# ATtiny45 register map
Vendor: Atmel; File version: 1.0
CPU: other r0p0, little endian, no MPU, no FPU, 4 interrupt priority bits
Registers are 8-bit, read-write, reset 0x0 unless marked. A register's access mark holds for its fields unless they carry their own. Offsets are from the block's base; [hi:lo] are bit positions; {n}, {i} and the like mark numbered series.

## CPU — CPU Registers
Base 0x00800031
0x00 GPIOR0 — General purpose register 0
0x01 GPIOR1 — General Purpose register 1
0x02 GPIOR2 — General Purpose IO register 2
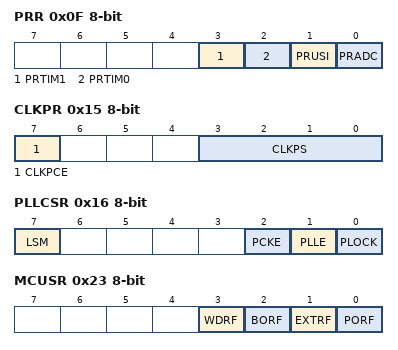
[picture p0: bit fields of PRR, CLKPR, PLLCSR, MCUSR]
0x0F PRR — Power Reduction Register
  [3] PRTIM1 — Power Reduction Timer/Counter1
  [2] PRTIM0 — Power Reduction Timer/Counter0
  [1] PRUSI — Power Reduction USI
  [0] PRADC — Power Reduction ADC
0x11 DWDR — debugWire data register (write-only for debugger)
0x15 CLKPR — Clock Prescale Register (read-only for debugger)
  [7] CLKPCE — Clock Prescaler Change Enable
  [3:0] CLKPS — Clock Prescaler Select Bits
    0=1; 1=2; 2=4; 3=8; 4=16; 5=32; 6=64; 7=128; 8=256
0x16 PLLCSR — PLL Control and status register
  [7] LSM — Low speed mode
  [2] PCKE — PCK Enable
  [1] PLLE — PLL Enable
  [0] PLOCK — PLL Lock detector
0x20 OSCCAL — Oscillator Calibration Register (read-only for debugger)
  [7:0] OSCCAL — Oscillator Calibration
0x23 MCUSR — MCU Status register (read-only for debugger)
  [3] WDRF — Watchdog Reset Flag
  [2] BORF — Brown-out Reset Flag
  [1] EXTRF — External Reset Flag
  [0] PORF — Power-On Reset Flag
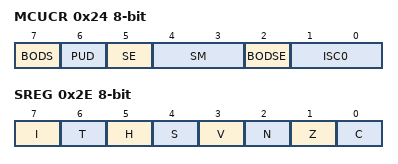
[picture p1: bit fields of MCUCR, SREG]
0x24 MCUCR — MCU Control Register
  [7] BODS — BOD Sleep
  [6] PUD — Pull-up Disable
  [5] SE — Sleep Enable
  [4:3] SM — Sleep Mode Select Bits
    0=IDLE; 1=ADC (ADC Noise Reduction (If Available)); 2=PDOWN (Power Down)
  [2] BODSE — BOD Sleep Enable
  [1:0] ISC0 — Interrupt Sense Control 0 bits
    0=LOW_LEVEL_OF_INTX; 1=ANY_LOGICAL_CHANGE_IN_INTX; 2=FALLING_EDGE_OF_INTX; 3=RISING_EDGE_OF_INTX
0x2C SP 16-bit (reset mask 0xFF) — Stack Pointer Bytes
0x2E SREG — Status Register
  [7] I — Global Interrupt Enable
  [6] T — Bit Copy Storage
  [5] H — Half Carry Flag
  [4] S — Sign Bit
  [3] V — Two's Complement Overflow Flag
  [2] N — Negative Flag
  [1] Z — Zero Flag
  [0] C — Carry Flag

## EEPROM
Base 0x0080003C
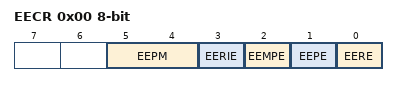
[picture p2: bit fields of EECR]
0x00 EECR — EEPROM Control Register
  [5:4] EEPM — EEPROM Programming Mode Bits
    0=ERASE_AND_WRITE_IN_ONE_OPERATION; 1=ERASE_ONLY; 2=WRITE_ONLY
  [3] EERIE — EEPROM Ready Interrupt Enable
  [2] EEMPE — EEPROM Master Write Enable
  [1] EEPE — EEPROM Write Enable
  [0] EERE — EEPROM Read Enable
0x01 EEDR — EEPROM Data Register
0x02 EEAR 16-bit (reset mask 0xFF) — EEPROM Address Register Bytes

## EXINT — External Interrupts
Base 0x00800035
0x00 PCMSK — Pin Change Enable Mask
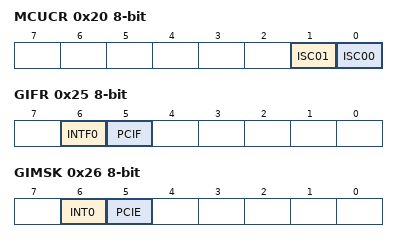
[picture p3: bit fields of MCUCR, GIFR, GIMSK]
0x20 MCUCR — MCU Control Register
  [1] ISC01 — Interrupt Sense Control 0 Bit 1
  [0] ISC00 — Interrupt Sense Control 0 Bit 0
    0=LOW_LEVEL_OF_INTX; 1=ANY_LOGICAL_CHANGE_ON_INTX
0x25 GIFR — General Interrupt Flag register (read-only for debugger)
  [6] INTF0 — External Interrupt Flag 0
  [5] PCIF — Pin Change Interrupt Flag
0x26 GIMSK — General Interrupt Mask Register
  [6] INT0 — External Interrupt Request 0 Enable
  [5] PCIE — Pin Change Interrupt Enable

## PORTB — I/O Port
Base 0x00800036
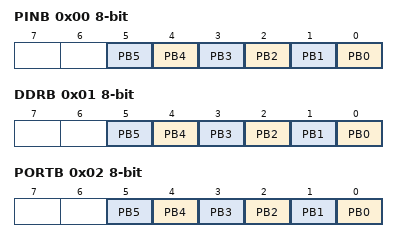
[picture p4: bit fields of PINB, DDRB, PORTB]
0x00 PINB — Input Pins, Port B (read-only for debugger)
  [n] PB{n} (n=0..5) — Pin B{n}
0x01 DDRB — Data Direction Register, Port B
  [n] PB{n} (n=0..5) — Pin B{n}
0x02 PORTB — Data Register, Port B
  [n] PB{n} (n=0..5) — Pin B{n}

## TC0 — Timer/Counter, 8-bit
Base 0x00800048
0x00 OCR0B — Timer/Counter0 Output Compare Register
0x01 OCR0A — Timer/Counter0 Output Compare Register
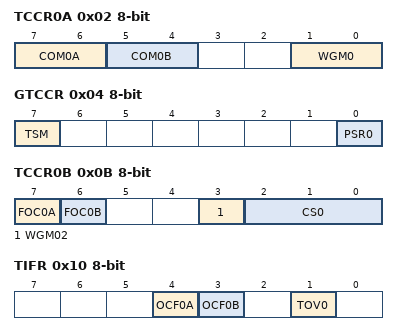
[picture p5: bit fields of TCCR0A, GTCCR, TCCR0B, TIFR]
0x02 TCCR0A — Timer/Counter Control Register A
  [7:6] COM0A — Compare Output Mode, Phase Correct PWM Mode
  [5:4] COM0B — Compare Output Mode, Fast PWm
  [1:0] WGM0 — Waveform Generation Mode
0x04 GTCCR — General Timer/Counter Control Register
  [7] TSM — Timer/Counter Synchronization Mode
  [0] PSR0 — Prescaler Reset Timer/Counter1 and Timer/Counter0
0x0A TCNT0 — Timer/Counter0
0x0B TCCR0B — Timer/Counter Control Register B
  [7] FOC0A — Force Output Compare A
  [6] FOC0B — Force Output Compare B
  [3] WGM02
  [2:0] CS0 — Clock Select
    0=NO_CLOCK_SOURCE_STOPPED; 1=RUNNING_NO_PRESCALING; 2=RUNNING_CLK_8; 3=RUNNING_CLK_64; 4=RUNNING_CLK_256; 5=RUNNING_CLK_1024; 6=RUNNING_EXTCLK_TN_FALLING_EDGE; 7=RUNNING_EXTCLK_TN_RISING_EDGE
0x10 TIFR — Timer/Counter0 Interrupt Flag register
  [4] OCF0A — Timer/Counter0 Output Compare Flag 0A
  [3] OCF0B — Timer/Counter0 Output Compare Flag 0B
  [1] TOV0 — Timer/Counter0 Overflow Flag
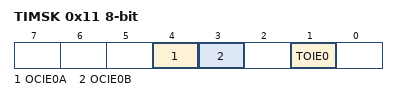
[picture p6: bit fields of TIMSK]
0x11 TIMSK — Timer/Counter Interrupt Mask Register
  [4] OCIE0A — Timer/Counter0 Output Compare Match A Interrupt Enable
  [3] OCIE0B — Timer/Counter0 Output Compare Match B Interrupt Enable
  [1] TOIE0 — Timer/Counter0 Overflow Interrupt Enable

## TC1 — Timer/Counter, 8-bit
Base 0x00800043
0x00 DTPS — Dead time prescaler register
  [1:0] DTPS
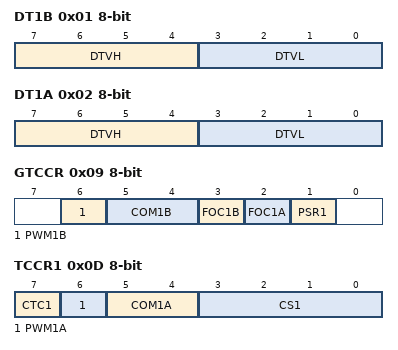
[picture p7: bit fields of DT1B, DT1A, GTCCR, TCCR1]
0x01 DT1B — Dead time value B
  [7:4] DTVH, [3:0] DTVL
0x02 DT1A — Dead time value register
  [7:4] DTVH, [3:0] DTVL
0x08 OCR1B — Output Compare Register
0x09 GTCCR — Timer counter control register
  [6] PWM1B — Pulse Width Modulator B Enable
  [5:4] COM1B — Comparator B Output Mode
  [3] FOC1B — Force Output Compare Match 1B
  [2] FOC1A — Force Output Compare 1A
  [1] PSR1 — Prescaler Reset Timer/Counter1
0x0A OCR1C — Output compare register
0x0B OCR1A — Output Compare Register
0x0C TCNT1 — Timer/Counter Register (read-only for debugger)
0x0D TCCR1 — Timer/Counter Control Register
  [7] CTC1 — Clear Timer/Counter on Compare Match
  [6] PWM1A — Pulse Width Modulator Enable
  [5:4] COM1A — Compare Output Mode, Bits
    0=DISCONNECTED_FROM_OCN_PWMN; 1=TOGGLE_OCN_PWMN_OUTPUT_LINE; 2=CLEAR_OCN_PWMN_OUTPUT_LINE; 3=SET_OCN_PWMN_OUTPUT_LINE
  [3:0] CS1 — Clock Select Bits
    0=NO_CLOCK_SOURCE_STOPPED; 1=RUNNING_NO_PRESCALING; 2=RUNNING_CLK_2; 3=RUNNING_CLK_4; 4=RUNNING_CLK_8; 5=RUNNING_CLK_16; 6=RUNNING_CLK_32; 7=RUNNING_CLK_64; 8=RUNNING_CLK_128; 9=RUNNING_CLK_256; 10=RUNNING_CLK_512; 11=RUNNING_CLK_1024; 12=RUNNING_CLK_2048; 13=RUNNING_CLK_4096; 14=RUNNING_CLK_8192; 15=RUNNING_CLK_16384
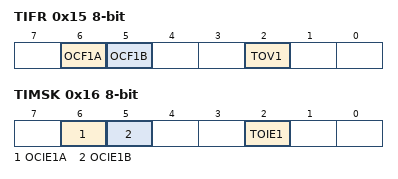
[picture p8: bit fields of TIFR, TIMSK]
0x15 TIFR — Timer/Counter Interrupt Flag Register
  [6] OCF1A — Timer/Counter1 Output Compare Flag 1A
  [5] OCF1B — Timer/Counter1 Output Compare Flag 1B
  [2] TOV1 — Timer/Counter1 Overflow Flag
0x16 TIMSK — Timer/Counter Interrupt Mask Register
  [6] OCIE1A — OCIE1A: Timer/Counter1 Output Compare Interrupt Enable
  [5] OCIE1B — OCIE1A: Timer/Counter1 Output Compare B Interrupt Enable
  [2] TOIE1 — Timer/Counter1 Overflow Interrupt Enable

## USI — Universal Serial Interface
Base 0x0080002D
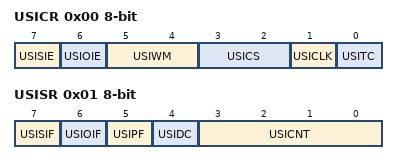
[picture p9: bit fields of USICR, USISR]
0x00 USICR — USI Control Register
  [7] USISIE — Start Condition Interrupt Enable
  [6] USIOIE — Counter Overflow Interrupt Enable
  [5:4] USIWM — USI Wire Mode Bits
    0=NORMAL_OPERATION; 1=THREE_WIRE_MODE; 2=TWO_WIRE_MODE; 3=TWO_WIRE_MODE_HELD_LOW
  [3:2] USICS — USI Clock Source Select Bits
  [1] USICLK — Clock Strobe
  [0] USITC — Toggle Clock Port Pin
0x01 USISR — USI Status Register (read-only for debugger)
  [7] USISIF — Start Condition Interrupt Flag
  [6] USIOIF — Counter Overflow Interrupt Flag
  [5] USIPF — Stop Condition Flag
  [4] USIDC — Data Output Collision
  [3:0] USICNT — USI Counter Value Bits
0x02 USIDR — USI Data Register
0x03 USIBR — USI Buffer Register (read-only for debugger)

## WDT — Watchdog Timer
Base 0x00800041
0x00 WDTCR — Watchdog Timer Control Register (read-only for debugger)
  [7] WDIF — Watchdog Timeout Interrupt Flag
  [6] WDIE — Watchdog Timeout Interrupt Enable
  [4] WDCE — Watchdog Change Enable
  [3] WDE — Watch Dog Enable
  [5:0] WDP — Watchdog Timer Prescaler Bits
    0=OSCILLATOR_CYCLES_2K; 1=OSCILLATOR_CYCLES_4K; 2=OSCILLATOR_CYCLES_8K; 3=OSCILLATOR_CYCLES_16K; 4=OSCILLATOR_CYCLES_32K; 5=OSCILLATOR_CYCLES_64K; 6=OSCILLATOR_CYCLES_128K; 7=OSCILLATOR_CYCLES_256K
